# CC3200 register map
Vendor: Texas Instruments; Series: SimpleLink; File version: 1.0
CPU: CM4 r0p1, little endian, MPU, no FPU, 3 interrupt priority bits
Registers are 32-bit, read-write, reset 0x0 unless marked. A register's access mark holds for its fields unless they carry their own. Offsets are from the block's base; [hi:lo] are bit positions; {n}, {i} and the like mark numbered series.

## DTHE
Base 0x44030000
0x810 SHA_IM — DTHE_SHA_IM
0x814 SHA_RIS — DTHE_SHA_RIS
0x818 SHA_MIS — DTHE_SHA_MIS
0x81C SHA_IC — DTHE_SHA_IC
0x820 AES_IM — DTHE_AES_IM
  [3] S_DOUT — DTHE_AES_IM
  [3] T_DOUT — DTHE_AES_IM
  [2] S_DIN — DTHE_AES_IM
  [2] T_DIN — DTHE_AES_IM
  [1] S_COUT — DTHE_AES_IM
  [1] T_COUT — DTHE_AES_IM
  [0] S_CIN — DTHE_AES_IM
  [0] T_CIN — DTHE_AES_IM
0x824 AES_RIS — DTHE_AES_RIS
0x828 AES_MIS — DTHE_AES_MIS
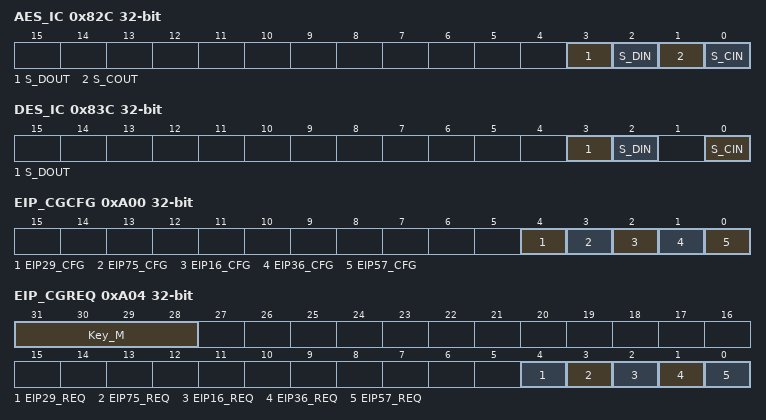
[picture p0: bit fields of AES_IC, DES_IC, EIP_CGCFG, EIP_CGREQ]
0x82C AES_IC — DTHE_AES_IC
  [3] S_DOUT — DTHE_AES_IC
  [2] S_DIN — DTHE_AES_IC
  [1] S_COUT — DTHE_AES_IC
  [0] S_CIN — DTHE_AES_IC
0x830 DES_IM — DTHE_DES_IM
  [3] S_DOUT — DTHE_DES_IM
  [3] T_DOUT — DTHE_DES_IM
  [2] S_DIN — DTHE_DES_IM
  [2] T_DIN — DTHE_DES_IM
  [0] S_CIN — DTHE_DES_IM
  [0] T_CIN — DTHE_DES_IM
0x834 DES_RIS — DTHE_DES_RIS
0x838 DES_MIS — DTHE_DES_MIS
0x83C DES_IC — DTHE_DES_IC
  [3] S_DOUT — DTHE_DES_IC
  [2] S_DIN — DTHE_DES_IC
  [0] S_CIN — DTHE_DES_IC
0xA00 EIP_CGCFG — DTHE_EIP_CGCFG
  [4] EIP29_CFG — DTHE_EIP_CGCFG
  [3] EIP75_CFG — DTHE_EIP_CGCFG
  [2] EIP16_CFG — DTHE_EIP_CGCFG
  [1] EIP36_CFG — DTHE_EIP_CGCFG
  [0] EIP57_CFG — DTHE_EIP_CGCFG
0xA04 EIP_CGREQ — DTHE_EIP_CGREQ
  [31:28] Key_M — DTHE_EIP_CGREQ
  [4] EIP29_REQ — DTHE_EIP_CGREQ
  [3] EIP75_REQ — DTHE_EIP_CGREQ
  [2] EIP16_REQ — DTHE_EIP_CGREQ
  [1] EIP36_REQ — DTHE_EIP_CGREQ
  [0] EIP57_REQ — DTHE_EIP_CGREQ
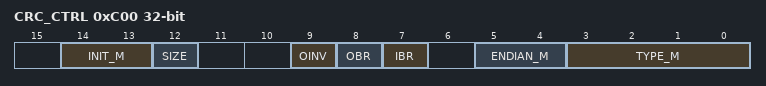
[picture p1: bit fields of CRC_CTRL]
0xC00 CRC_CTRL — DTHE_CRC_CTRL
  [14:13] INIT_M — DTHE_CRC_CTRL
  [12] SIZE — DTHE_CRC_CTRL
  [9] OINV — DTHE_CRC_CTRL
  [8] OBR — DTHE_CRC_CTRL
  [7] IBR — DTHE_CRC_CTRL
  [5:4] ENDIAN_M — DTHE_CRC_CTRL
  [3:0] TYPE_M — DTHE_CRC_CTRL
0xC10 CRC_SEED — DTHE_CRC_SEED
  [31:0] SEED_M
0xC14 CRC_DIN — DTHE_CRC_DIN
  [31:0] DATA_IN_M
0xC18 CRC_RSLT_PP — DTHE_CRC_RSLT_PP
  [31:0] RSLT_PP_M
{0xF00+4i} RAND_KEY{i} (i=0..3) — DTHE_RAND_KEY{i}
  [31:0] KEY_M

## FLASH_CTRL — FLASH_CONTROL
Base 0x400FD000
0x00 FMA — FLASH_CTRL_FMA
  [17:0] OFFSET_M
0x04 FMD — FLASH_CTRL_FMD
  [31:0] DATA_M
0x08 FMC — FLASH_CTRL_FMC
  [21:17] WRKEY — FLASH_CTRL_FMC
  [21:17] _WRKEY — FLASH_CTRL_FMC
  [31:16] WRKEY_M — FLASH_CTRL_FMC
  [31:16] _WRKEY_M — FLASH_CTRL_FMC
  [3] COMT — FLASH_CTRL_FMC
  [2] MERASE1 — FLASH_CTRL_FMC
  [1] ERASE — FLASH_CTRL_FMC
  [0] WRITE — FLASH_CTRL_FMC
  [0] _WRBUF — FLASH_CTRL_FMC
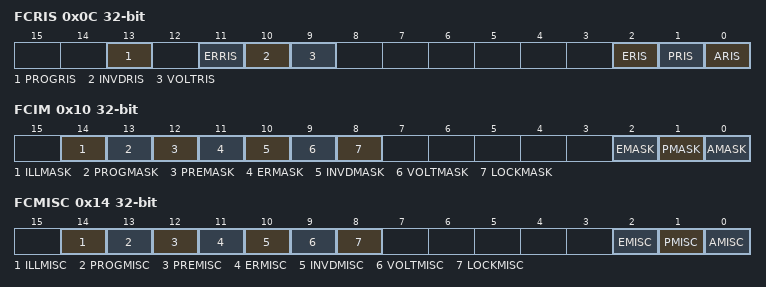
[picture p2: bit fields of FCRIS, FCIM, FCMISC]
0x0C FCRIS — FLASH_CTRL_FCRIS
  [13] PROGRIS — FLASH_CTRL_FCRIS
  [11] ERRIS — FLASH_CTRL_FCRIS
  [10] INVDRIS — FLASH_CTRL_FCRIS
  [9] VOLTRIS — FLASH_CTRL_FCRIS
  [2] ERIS — FLASH_CTRL_FCRIS
  [1] PRIS — FLASH_CTRL_FCRIS
  [0] ARIS — FLASH_CTRL_FCRIS
0x10 FCIM — FLASH_CTRL_FCIM
  [14] ILLMASK — FLASH_CTRL_FCIM
  [13] PROGMASK — FLASH_CTRL_FCIM
  [12] PREMASK — FLASH_CTRL_FCIM
  [11] ERMASK — FLASH_CTRL_FCIM
  [10] INVDMASK — FLASH_CTRL_FCIM
  [9] VOLTMASK — FLASH_CTRL_FCIM
  [8] LOCKMASK — FLASH_CTRL_FCIM
  [2] EMASK — FLASH_CTRL_FCIM
  [1] PMASK — FLASH_CTRL_FCIM
  [0] AMASK — FLASH_CTRL_FCIM
0x14 FCMISC — FLASH_CTRL_FCMISC
  [14] ILLMISC — FLASH_CTRL_FCMISC
  [13] PROGMISC — FLASH_CTRL_FCMISC
  [12] PREMISC — FLASH_CTRL_FCMISC
  [11] ERMISC — FLASH_CTRL_FCMISC
  [10] INVDMISC — FLASH_CTRL_FCMISC
  [9] VOLTMISC — FLASH_CTRL_FCMISC
  [8] LOCKMISC — FLASH_CTRL_FCMISC
  [2] EMISC — FLASH_CTRL_FCMISC
  [1] PMISC — FLASH_CTRL_FCMISC
  [0] AMISC — FLASH_CTRL_FCMISC
0x20 FMC2 — FLASH_CTRL_FMC2
  [21:17] WRKEY — FLASH_CTRL_FMC2
  [31:16] WRKEY_M — FLASH_CTRL_FMC2
  [0] WRBUF — FLASH_CTRL_FMC2
0x30 FWBVAL — FLASH_CTRL_FWBVAL
  [31:0] FWBN_M
0x100 FWB1 — FLASH_CTRL_FWB1
  [31:0] DATA_M — FLASH_CTRL_FWB1
  [31:0] _DATA_M — FLASH_CTRL_FWB1
  [31:0] _DATA_M_{n} (n=2..10) — FLASH_CTRL_FWB1
0x104 FWB2 — FLASH_CTRL_FWB2
  [31:0] DATA_M — FLASH_CTRL_FWB2
  [31:0] _DATA_M — FLASH_CTRL_FWB2
  [31:0] _DATA_M_{n} (n=2..10) — FLASH_CTRL_FWB2
0x108 FWB3 — FLASH_CTRL_FWB3
  [31:0] DATA_M — FLASH_CTRL_FWB3
  [31:0] _DATA_M — FLASH_CTRL_FWB3
  [31:0] _DATA_M_2 — FLASH_CTRL_FWB3
  [31:0] _DATA_M_3 — FLASH_CTRL_FWB3
{0xFC+4i} FWB{i} (i=4..32) — FLASH_CTRL_FWB{i}
  [31:0] DATA_M
0xFC0 FSIZE — FLASH_CTRL_FSIZE
  [15:0] SIZE_M
0xFC4 SSIZE — FLASH_CTRL_SSIZE
  [15:0] SRAM_SIZE_M

## UDMA
Base 0x400FF000
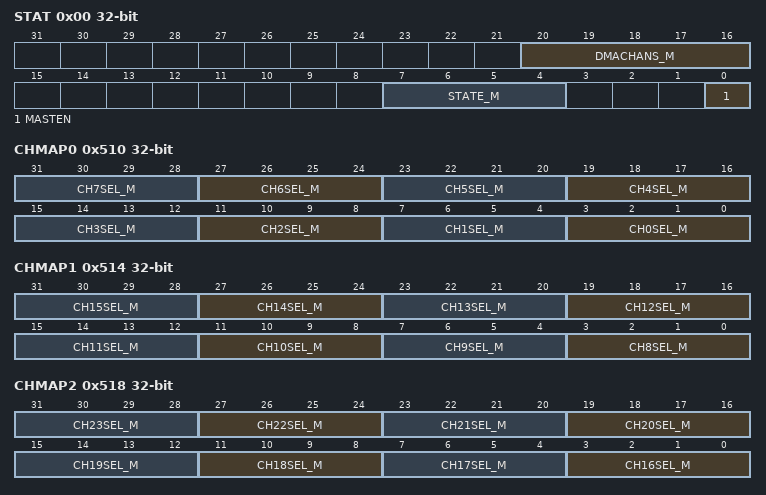
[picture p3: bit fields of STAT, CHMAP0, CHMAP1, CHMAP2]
0x00 STAT — UDMA_STAT
  [20:16] DMACHANS_M — UDMA_STAT
  [7:4] STATE_M — UDMA_STAT
  [0] MASTEN — UDMA_STAT
0x04 CFG — UDMA_CFG
  [0] MASTEN
0x08 CTLBASE — UDMA_CTLBASE
  [31:10] ADDR_M
0x0C ALTBASE — UDMA_ALTBASE
  [31:0] ADDR_M
0x10 WAITSTAT — UDMA_WAITSTAT
  [31:0] WAITREQ_M
0x14 SWREQ — UDMA_SWREQ
  [31:0] M
0x18 USEBURSTSET — UDMA_USEBURSTSET
  [31:0] SET_M
0x1C USEBURSTCLR — UDMA_USEBURSTCLR
  [31:0] CLR_M
0x20 REQMASKSET — UDMA_REQMASKSET
  [31:0] SET_M
0x24 REQMASKCLR — UDMA_REQMASKCLR
  [31:0] CLR_M
0x28 ENASET — UDMA_ENASET
  [31:0] CHENSET_M
0x2C ENACLR — UDMA_ENACLR
  [31:0] CLR_M
0x30 ALTSET — UDMA_ALTSET
  [31:0] SET_M
0x34 ALTCLR — UDMA_ALTCLR
  [31:0] CLR_M
0x38 PRIOSET — UDMA_PRIOSET
  [31:0] SET_M
0x3C PRIOCLR — UDMA_PRIOCLR
  [31:0] CLR_M
0x4C ERRCLR — UDMA_ERRCLR
  [0] ERRCLR
0x500 CHASGN — UDMA_CHASGN
  [31:0] M
0x504 CHIS — UDMA_CHIS
  [31:0] M
0x510 CHMAP0 — UDMA_CHMAP0
  [4n+3:4n] CH{n}SEL_M (n=0..7) — UDMA_CHMAP0
0x514 CHMAP1 — UDMA_CHMAP1
  [4n-29:4n-32] CH{n}SEL_M (n=8..15) — UDMA_CHMAP1
0x518 CHMAP2 — UDMA_CHMAP2
  [4n-61:4n-64] CH{n}SEL_M (n=16..23) — UDMA_CHMAP2
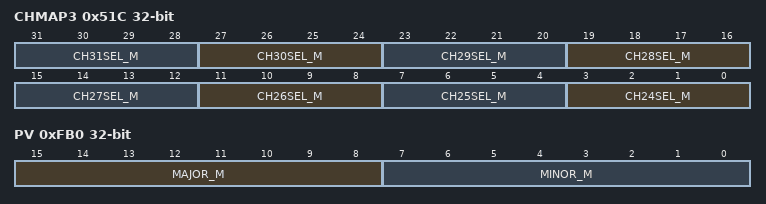
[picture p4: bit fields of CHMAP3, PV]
0x51C CHMAP3 — UDMA_CHMAP3
  [4n-93:4n-96] CH{n}SEL_M (n=24..31) — UDMA_CHMAP3
0xFB0 PV — UDMA_PV
  [15:8] MAJOR_M — UDMA_PV
  [7:0] MINOR_M — UDMA_PV

## WDT
Base 0x40000000
0x00 LOAD — WDT_LOAD
  [31:0] M
0x04 VALUE — WDT_VALUE
  [31:0] M
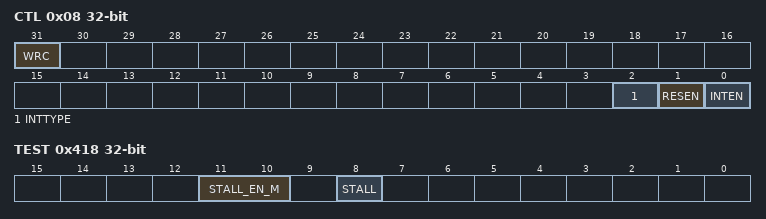
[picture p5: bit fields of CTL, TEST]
0x08 CTL — WDT_CTL
  [31] WRC — WDT_CTL
  [2] INTTYPE — WDT_CTL
  [1] RESEN — WDT_CTL
  [0] INTEN — WDT_CTL
0x0C ICR — WDT_ICR
  [31:0] M
0x10 RIS — WDT_RIS
  [0] WDTRIS
0x14 MIS — WDT_MIS
  [0] WDTMIS
0x418 TEST — WDT_TEST
  [11:10] STALL_EN_M — WDT_TEST
  [8] STALL — WDT_TEST
0xC00 LOCK — WDT_LOCK
  [31:0] M
